VERSION "WUFR 24.1.0"

BS_: 1000000 : 0,0

BU_: FSB DAQ RSB CTRLB

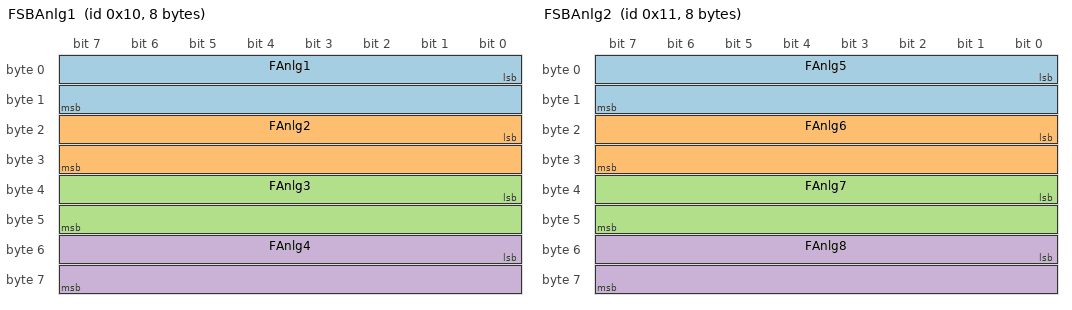
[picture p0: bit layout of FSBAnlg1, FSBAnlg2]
BO_ 16 FSBAnlg1: 8 FSB
 SG_ FAnlg1 : 0|16@1+ (0.001,0) [0|5] "V" DAQ
 SG_ FAnlg2 : 16|16@1+ (0.001,0) [0|5] "V" DAQ
 SG_ FAnlg3 : 32|16@1+ (0.001,0) [0|5] "V" DAQ
 SG_ FAnlg4 : 48|16@1+ (0.001,0) [0|5] "V" DAQ

BO_ 17 FSBAnlg2: 8 FSB
 SG_ FAnlg5 : 0|16@1+ (0.001,0) [0|5] "V" DAQ
 SG_ FAnlg6 : 16|16@1+ (0.001,0) [0|5] "V" DAQ
 SG_ FAnlg7 : 32|16@1+ (0.001,0) [0|5] "V" DAQ
 SG_ FAnlg8 : 48|16@1+ (0.001,0) [0|5] "V" DAQ

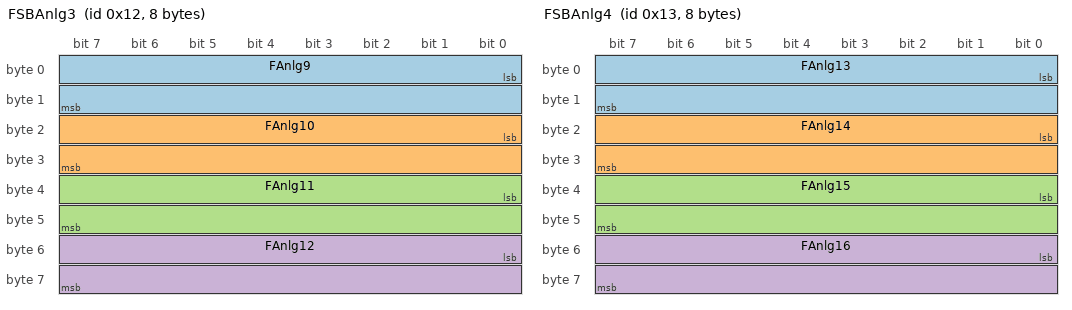
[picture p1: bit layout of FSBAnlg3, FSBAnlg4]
BO_ 18 FSBAnlg3: 8 FSB
 SG_ FAnlg9 : 0|16@1+ (0.001,0) [0|5] "V" DAQ
 SG_ FAnlg10 : 16|16@1+ (0.001,0) [0|5] "V" DAQ
 SG_ FAnlg11 : 32|16@1+ (0.001,0) [0|5] "V" DAQ
 SG_ FAnlg12 : 48|16@1+ (0.001,0) [0|5] "V" DAQ

BO_ 19 FSBAnlg4: 8 FSB
 SG_ FAnlg13 : 0|16@1+ (0.001,0) [0|5] "V" DAQ
 SG_ FAnlg14 : 16|16@1+ (0.001,0) [0|5] "V" DAQ
 SG_ FAnlg15 : 32|16@1+ (0.001,0) [0|5] "V" DAQ
 SG_ FAnlg16 : 48|16@1+ (0.001,0) [0|5] "V" DAQ

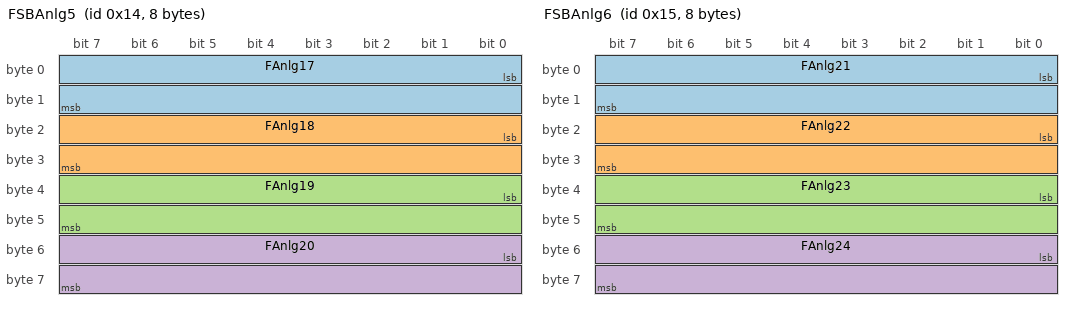
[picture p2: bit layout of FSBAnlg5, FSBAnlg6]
BO_ 20 FSBAnlg5: 8 FSB
 SG_ FAnlg17 : 0|16@1+ (0.001,0) [0|5] "V" DAQ
 SG_ FAnlg18 : 16|16@1+ (0.001,0) [0|5] "V" DAQ
 SG_ FAnlg19 : 32|16@1+ (0.001,0) [0|5] "V" DAQ
 SG_ FAnlg20 : 48|16@1+ (0.001,0) [0|5] "V" DAQ

BO_ 21 FSBAnlg6: 8 FSB
 SG_ FAnlg21 : 0|16@1- (1,0) [-32768|32767] "#" DAQ
 SG_ FAnlg22 : 16|16@1- (1,0) [-32768|32767] "#" DAQ
 SG_ FAnlg23 : 32|16@1- (1,0) [-32768|32767] "#" DAQ
 SG_ FAnlg24 : 48|16@1- (1,0) [-32768|32767] "#" DAQ

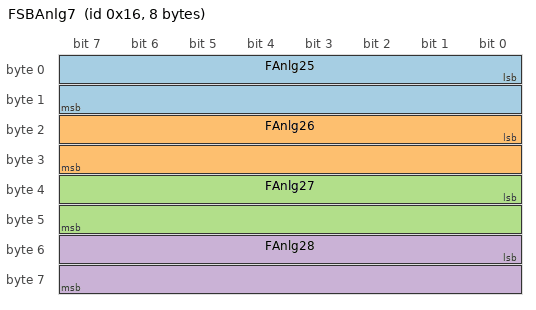
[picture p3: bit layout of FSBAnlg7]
BO_ 22 FSBAnlg7: 8 FSB
 SG_ FAnlg25 : 0|16@1- (1,0) [-32768|32767] "#" DAQ
 SG_ FAnlg26 : 16|16@1- (1,0) [-32768|32767] "#" DAQ
 SG_ FAnlg27 : 32|16@1- (1,0) [-32768|32767] "#" DAQ
 SG_ FAnlg28 : 48|16@1- (1,0) [-32768|32767] "#" DAQ

BO_ 23 FSBAnlg8: 8 FSB
 SG_ FAnlg29 : 0|16@1+ (1,0) [-32768|32767] "#" DAQ

BO_ 49 CTRLBrd: 1 CTRLB
 SG_ DRS : 0|1@1+ (1,0) [0|1] "Open:1/Close:0" DAQ
 SG_ ClutchPosition : 8|8@1+ (1,0) [0|360] "Deg" DAQ

CM_ BU_ RSB "Rear sensor board";
CM_ BU_ CTRLB "Control board";
BA_DEF_DEF_  "GenMsgCycleTime" 100;
